# CH569 register map
Vendor: WCH Ltd.; File version: 1.0
Registers are 32-bit, read-write, reset 0x0 unless marked. A register's access mark holds for its fields unless they carry their own. Offsets are from the block's base; [hi:lo] are bit positions.

## UART0
Base 0x40003000
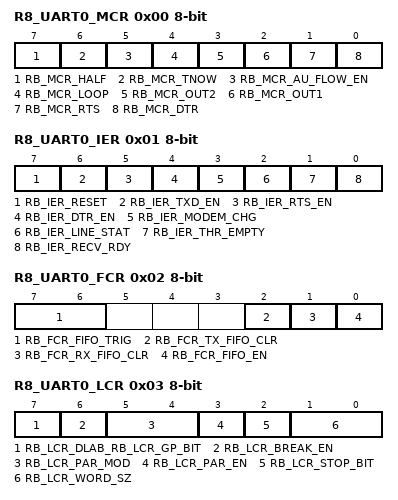
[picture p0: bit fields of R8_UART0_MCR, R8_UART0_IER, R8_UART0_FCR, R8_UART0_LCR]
0x00 R8_UART0_MCR 8-bit — UART0 modem control
  [7] RB_MCR_HALF — UART0 enable half-duplex
  [6] RB_MCR_TNOW — UART0 enable TNOW output on DTR pin
  [5] RB_MCR_AU_FLOW_EN — UART0 enable autoflow control
  [4] RB_MCR_LOOP — UART0 enable local loop back
  [3] RB_MCR_OUT2 — UART control OUT2
  [2] RB_MCR_OUT1 — UART0 control OUT1
  [1] RB_MCR_RTS — UART0 control RTS
  [0] RB_MCR_DTR — UART0 control DTR
0x01 R8_UART0_IER 8-bit — UART0 interrupt enable
  [7] RB_IER_RESET — UART software reset control, high action, auto clear
  [6] RB_IER_TXD_EN — UART TXD pin enable
  [5] RB_IER_RTS_EN — UART0 RTS output pin enable
  [4] RB_IER_DTR_EN — UART0 DTR/TNOW output pin enable
  [3] RB_IER_MODEM_CHG — UART0 interrupt enable for modem status change
  [2] RB_IER_LINE_STAT — UART interrupt enable for receiver line status
  [1] RB_IER_THR_EMPTY — UART interrupt enable for THR empty
  [0] RB_IER_RECV_RDY — UART interrupt enable for receiver data ready
0x02 R8_UART0_FCR 8-bit — UART0 FIFO control
  [7:6] RB_FCR_FIFO_TRIG — UART receiver FIFO trigger level
  [2] RB_FCR_TX_FIFO_CLR — clear UART transmitter FIFO, high action, auto clear
  [1] RB_FCR_RX_FIFO_CLR — clear UART receiver FIFO, high action, auto clear
  [0] RB_FCR_FIFO_EN — UART FIFO enable
0x03 R8_UART0_LCR 8-bit — UART0 line control
  [7] RB_LCR_DLAB_RB_LCR_GP_BIT — UART reserved bit _UART general purpose bit
  [6] RB_LCR_BREAK_EN — UART break control enable
  [5:4] RB_LCR_PAR_MOD — UART parity mode
  [3] RB_LCR_PAR_EN — UART parity enable
  [2] RB_LCR_STOP_BIT — UART stop bit length
  [1:0] RB_LCR_WORD_SZ — UART word bit length
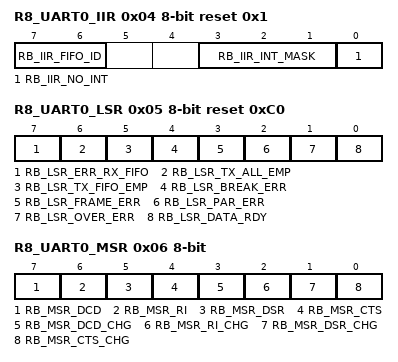
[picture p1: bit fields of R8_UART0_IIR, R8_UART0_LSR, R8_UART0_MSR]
0x04 R8_UART0_IIR 8-bit ro reset 0x1 — UART0 interrupt identification
  [7:6] RB_IIR_FIFO_ID — UART FIFO enabled flag
  [3:1] RB_IIR_INT_MASK — UART interrupt flag bit mask
  [0] RB_IIR_NO_INT — UART no interrupt flag
0x05 R8_UART0_LSR 8-bit ro reset 0xC0 — UART0 line status
  [7] RB_LSR_ERR_RX_FIFO — indicate error in UART receiver fifo
  [6] RB_LSR_TX_ALL_EMP — UART transmitter all empty status
  [5] RB_LSR_TX_FIFO_EMP — UART transmitter fifo empty status
  [4] RB_LSR_BREAK_ERR — UART receiver break error
  [3] RB_LSR_FRAME_ERR — UART receiver frame error
  [2] RB_LSR_PAR_ERR — UART receiver frame error
  [1] RB_LSR_OVER_ERR — UART receiver overrun error
  [0] RB_LSR_DATA_RDY — UART receiver fifo data ready status
0x06 R8_UART0_MSR 8-bit ro — UART0 modem status
  [7] RB_MSR_DCD — UART0 DCD action status
  [6] RB_MSR_RI — UART0 RI action status
  [5] RB_MSR_DSR — UART0 DSR action status
  [4] RB_MSR_CTS — UART0 CTS action status
  [3] RB_MSR_DCD_CHG — UART0 DCD changed status, high action
  [2] RB_MSR_RI_CHG — UART0 RI changed status, high action
  [1] RB_MSR_DSR_CHG — UART0 DSR changed status, high action
  [0] RB_MSR_CTS_CHG — UART0 CTS changed status, high action
0x08 R8_UART0_RBR_R8_UART0_THR 8-bit — UART0 receiver buffer, receiving byte _ UART0 transmitter holding, transmittal byte
  [7:0] R8_UART0_RBR_R8_UART0_THR — UART receiver buffer, receiving byte_ UART transmitter holding, transmittal byte
0x0A R8_UART0_RFC 8-bit ro — UART0 receiver FIFO count
  [7:0] R8_UART_RFC — UART receiver FIFO count
0x0B R8_UART0_TFC 8-bit ro — UART0 transmitter FIFO count
  [7:0] R8_UART0_TFC — UART transmitter FIFO count
0x0C R16_UART0_DL 16-bit — UART0 divisor latch
  [15:0] R16_UART0_DL — UART divisor latch
0x0E R8_UART0_DIV 8-bit — UART0 pre-divisor latch byte
  [7:0] R8_UART0_ADR — UART pre-divisor latch byte
0x0F R8_UART0_ADR 8-bit reset 0xFF — UART0 slave address

## UART1
Base 0x40003400
Registers as UART0 (with UART0 read as UART1), without R8_UART0_MSR, R8_UART0_ADR; these are added or differ:
0x00 R8_UART1_MCR 8-bit — UART1 modem control
  [3] RB_MCR_OUT2 — UART1 control OUT2
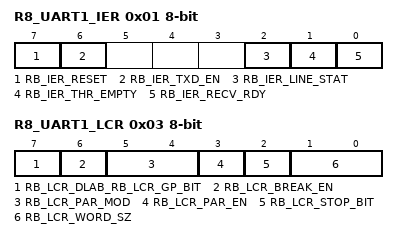
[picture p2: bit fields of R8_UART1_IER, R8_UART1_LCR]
0x01 R8_UART1_IER 8-bit — UART1 interrupt enable
  [7] RB_IER_RESET — UART software reset control, high action, auto clear
  [6] RB_IER_TXD_EN — UART TXD pin enable
  [2] RB_IER_LINE_STAT — UART interrupt enable for receiver line status
  [1] RB_IER_THR_EMPTY — UART interrupt enable for THR empty
  [0] RB_IER_RECV_RDY — UART interrupt enable for receiver data ready
0x03 R8_UART1_LCR 8-bit — UART1 line control
  [7] RB_LCR_DLAB_RB_LCR_GP_BIT — UART reserved bit _ UART general purpose bit
  [6] RB_LCR_BREAK_EN — UART break control enable
  [5:4] RB_LCR_PAR_MOD — UART parity mode
  [3] RB_LCR_PAR_EN — UART parity enable
  [2] RB_LCR_STOP_BIT — UART stop bit length
  [1:0] RB_LCR_WORD_SZ — UART word bit length
0x0A R8_UART1_RFC 8-bit ro — UART1 receiver FIFO count
  [7:0] R8_UART1_RFC — UART receiver FIFO count
0x0E R8_UART1_DIV 8-bit — UART1 pre-divisor latch byte
  [7:0] R8_UART1_DIV — UART pre-divisor latch byte

## UART2
Base 0x40003800
Registers as UART1 (with UART1 read as UART2); these are added or differ:
0x00 R8_UART2_MCR 8-bit — UART2 modem control
  [3] RB_MCR_OUT2 — UART control OUT2
0x08 R8_UART2_RBR_R8_UART2_THR 8-bit — UART2 receiver buffer, receiving byte _ UART2 transmitter holding, transmittal byte
  [7:0] R8_UART_RBR_R8_UART_THR — UART receiver buffer, receiving byte_ UART transmitter holding, transmittal byte

## UART3
Base 0x40003C00
Registers as UART2 (with UART2 read as UART3); these are added or differ:
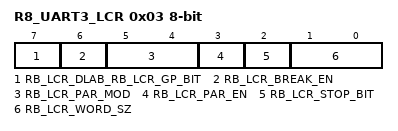
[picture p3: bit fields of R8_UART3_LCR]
0x03 R8_UART3_LCR 8-bit — UART3 line control
  [7] RB_LCR_DLAB_RB_LCR_GP_BIT — UART reserved bit and UART general purpose bit
  [6] RB_LCR_BREAK_EN — UART break control enable
  [5:4] RB_LCR_PAR_MOD — UART parity mode
  [3] RB_LCR_PAR_EN — UART parity enable
  [2] RB_LCR_STOP_BIT — UART stop bit length
  [1:0] RB_LCR_WORD_SZ — UART word bit length
0x08 R8_UART3_RBR_R8_UART3_THR 8-bit — UART3 receiver buffer, receiving byte _ UART3 transmitter holding, transmittal byte
  [7:0] R8_UART3_RBR_R8_UART3_THR — UART receiver buffer, receiving byte _ UART transmitter holding, transmittal byte
